# alb32r003x register map
Vendor: ALB; Series: ALB RT SoC
CPU: ALB XF, little endian
Registers are 32-bit, access not given, reset 0x0 unless marked. A register's access mark holds for its fields unless they carry their own. Offsets are from the block's base; [hi:lo] are bit positions.

## EQEP1
Base 0x21010000
Same registers: EQEP2 0x21010400
0x00 QPOSCNT
  [31:0] QPOSCNT — Position Counter
0x04 QPOSINIT
  [31:0] QPOSINIT — Position Counter Init
0x08 QPOSMAX
  [31:0] QPOSMAX — Maximum Position Count
0x0C QPOSCMP
  [31:0] QPOSCMP — Position Compare
0x10 QPOSILAT
  [31:0] QPOSILAT — Index Position Latch
0x14 QPOSSLAT
  [31:0] QPOSSLAT — Strobe Position Latch
0x18 QPOSLAT
  [31:0] QPOSLAT — Position Latch
0x1C QUTMR
  [31:0] QUTMR — QEP Unit Timer
0x20 QUPRD
  [31:0] QUPRD — QEP Unit Period
0x24 QWDTMR 16-bit
  [15:0] QWDTMR — QEP Watchdog Timer
0x26 QWDPRD 16-bit
  [15:0] QWDPRD — QEP Watchdog Period
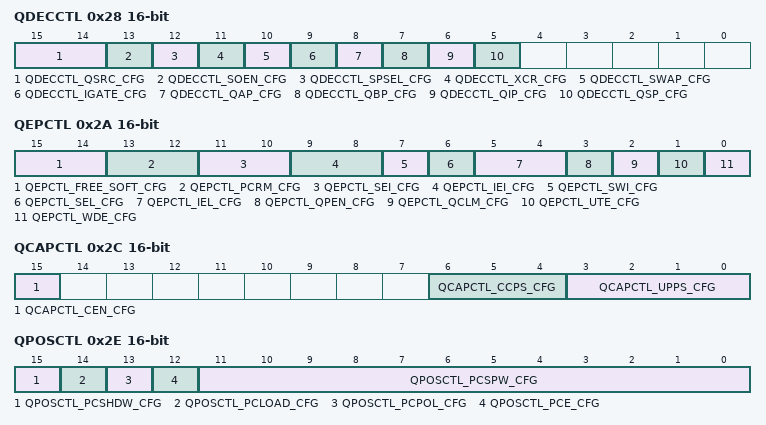
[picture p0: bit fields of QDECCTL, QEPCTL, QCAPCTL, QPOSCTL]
0x28 QDECCTL 16-bit
  [15:14] QDECCTL_QSRC_CFG — Position-counter source selection
  [13] QDECCTL_SOEN_CFG — Sync output-enable
  [12] QDECCTL_SPSEL_CFG — Sync output pin selection
  [11] QDECCTL_XCR_CFG — External Clock Rate
  [10] QDECCTL_SWAP_CFG — CLK/DIR Signal Source for Position Counter
  [9] QDECCTL_IGATE_CFG — Index pulse gating option
  [8] QDECCTL_QAP_CFG — Sync output-enable
  [7] QDECCTL_QBP_CFG — Sync output pin selection
  [6] QDECCTL_QIP_CFG — External Clock Rate
  [5] QDECCTL_QSP_CFG — CLK/DIR Signal Source for Position Counter
0x2A QEPCTL 16-bit
  [15:14] QEPCTL_FREE_SOFT_CFG — Emulation mode
  [13:12] QEPCTL_PCRM_CFG — Postion counter reset
  [11:10] QEPCTL_SEI_CFG — Strobe event initialization of position counter
  [9:8] QEPCTL_IEI_CFG — Index event init of position count
  [7] QEPCTL_SWI_CFG — Software init position counter
  [6] QEPCTL_SEL_CFG — Strobe event latch of position counter
  [5:4] QEPCTL_IEL_CFG — Index event latch of position counter (software index marker)
  [3] QEPCTL_QPEN_CFG — Quadrature position counter enable/software reset
  [2] QEPCTL_QCLM_CFG — QEP capture latch mode
  [1] QEPCTL_UTE_CFG — QEP unit timer enable
  [0] QEPCTL_WDE_CFG — QEP watchdog enable
0x2C QCAPCTL 16-bit
  [15] QCAPCTL_CEN_CFG — Enable eQEP capture
  [6:4] QCAPCTL_CCPS_CFG — eQEP capture timer clock prescaler
  [3:0] QCAPCTL_UPPS_CFG — Unit position event prescaler
0x2E QPOSCTL 16-bit
  [15] QPOSCTL_PCSHDW_CFG — Position compare of shadow enable
  [14] QPOSCTL_PCLOAD_CFG — Position compare of shadow load
  [13] QPOSCTL_PCPOL_CFG — Polarity of sync output
  [12] QPOSCTL_PCE_CFG — Position compare enable/disable
  [11:0] QPOSCTL_PCSPW_CFG — Select-position-compare sync output pulse width
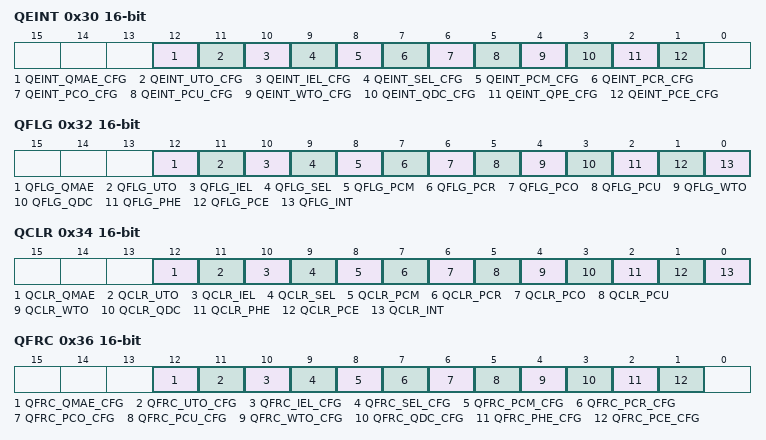
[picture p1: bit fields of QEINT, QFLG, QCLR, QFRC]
0x30 QEINT 16-bit
  [12] QEINT_QMAE_CFG — QMA Error Interrupt enable
  [11] QEINT_UTO_CFG — Unit time out interrupt enable
  [10] QEINT_IEL_CFG — Index event latch interrupt enable
  [9] QEINT_SEL_CFG — Strobe event latch interrupt enable
  [8] QEINT_PCM_CFG — Position-compare match interrupt enable
  [7] QEINT_PCR_CFG — Position-compare ready interrupt enable
  [6] QEINT_PCO_CFG — Position counter overflow interrupt enable
  [5] QEINT_PCU_CFG — Position counter underflow interrupt enable
  [4] QEINT_WTO_CFG — Watchdog time out interrupt enable
  [3] QEINT_QDC_CFG — Quadrature direction change interrupt enable
  [2] QEINT_QPE_CFG — Quadrature phase error interrupt enable
  [1] QEINT_PCE_CFG — Position counter error interrupt enable
0x32 QFLG 16-bit
  [12] QFLG_QMAE — QMA Error interrupt flag
  [11] QFLG_UTO — Unit time out interrupt flag
  [10] QFLG_IEL — Index event latch interrupt flag
  [9] QFLG_SEL — Strobe event latch interrupt flag
  [8] QFLG_PCM — eQEP compare match event interrupt flag
  [7] QFLG_PCR — Position-compare ready interrupt flag
  [6] QFLG_PCO — Position counter overflow interrupt flag
  [5] QFLG_PCU — Position counter underflow interrupt flag
  [4] QFLG_WTO — Watchdog timeout interrupt flag
  [3] QFLG_QDC — Quadrature direction change interrupt flag
  [2] QFLG_PHE — Quadrature phase error interrupt flag
  [1] QFLG_PCE — Position counter error interrupt flag
  [0] QFLG_INT — Global interrupt status flag
0x34 QCLR 16-bit
  [12] QCLR_QMAE — Clear QMA Error interrupt flag
  [11] QCLR_UTO — Clear unit time out interrupt flag
  [10] QCLR_IEL — Clear index event latch interrupt flag
  [9] QCLR_SEL — Clear strobe event latch interrupt flag
  [8] QCLR_PCM — Clear eQEP compare match event interrupt flag
  [7] QCLR_PCR — Clear position-compare ready interrupt flag
  [6] QCLR_PCO — Clear position counter overflow interrupt flag
  [5] QCLR_PCU — Clear position counter underflow interrupt flag
  [4] QCLR_WTO — Clear watchdog timeout interrupt flag
  [3] QCLR_QDC — Clear quadrature direction change interrupt flag
  [2] QCLR_PHE — Clear quadrature phase error interrupt flag
  [1] QCLR_PCE — Clear position counter error interrupt flag
  [0] QCLR_INT — Global interrupt clear flag
0x36 QFRC 16-bit
  [12] QFRC_QMAE_CFG — Force QMA error interrupt
  [11] QFRC_UTO_CFG — Force unit time out interrupt
  [10] QFRC_IEL_CFG — Force index event latch interrupt
  [9] QFRC_SEL_CFG — Force strobe event latch interrupt
  [8] QFRC_PCM_CFG — Force position-compare match interrupt
  [7] QFRC_PCR_CFG — Force position-compare ready interrupt
  [6] QFRC_PCO_CFG — Force position counter overflow interrupt
  [5] QFRC_PCU_CFG — Force position counter underflow interrupt
  [4] QFRC_WTO_CFG — Force watchdog time out interrupt
  [3] QFRC_QDC_CFG — Force quadrature direction change interrupt
  [2] QFRC_PHE_CFG — Force quadrature phase error interrupt
  [1] QFRC_PCE_CFG — Force position counter error interrupt
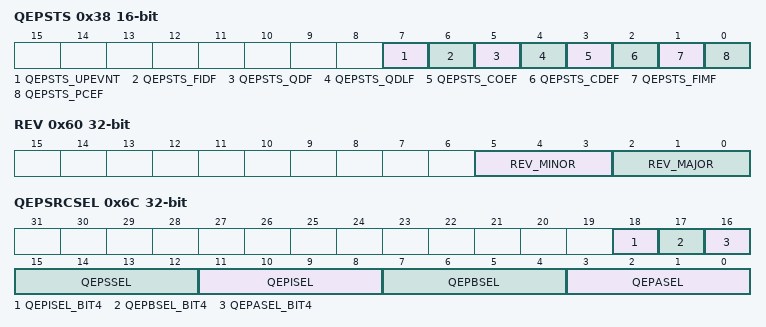
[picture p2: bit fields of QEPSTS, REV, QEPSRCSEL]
0x38 QEPSTS 16-bit
  [7] QEPSTS_UPEVNT — Unit position event flag
  [6] QEPSTS_FIDF — Direction on the first index marker
  [5] QEPSTS_QDF — Quadrature direction flag
  [4] QEPSTS_QDLF — eQEP direction latch flag
  [3] QEPSTS_COEF — Capture overflow error flag
  [2] QEPSTS_CDEF — Capture direction error flag
  [1] QEPSTS_FIMF — First index marker flag
  [0] QEPSTS_PCEF — Position counter error flag.
0x3A QCTMR 16-bit
  [15:0] QCTMR — This register provides time base for edge capture unit.
0x3C QCPRD 16-bit
  [15:0] QCPRD — This register holds the period count value between the last
0x3E QCTMRLAT 16-bit
  [15:0] QCTMRLAT — The eQEP capture timer value can be latched into this register
0x40 QCPRDLAT 16-bit
  [15:0] QCPRDLAT — eQEP capture period value can be latched into this register on two
0x60 REV
  [5:3] REV_MINOR — This field specifies the Minor Revision number for the eQEP IP.
  [2:0] REV_MAJOR — This field specifies the Major Revision number for the eQEP IP.
0x64 QEPSTROBESEL
  [1:0] QEPSTROBESEL_CFG — Strobe source select:
0x68 QMACTRL
  [2:0] QMACTRL_MODE_CFG — Select Mode for QMA mode:
0x6C QEPSRCSEL
  [18] QEPISEL_BIT4 — QEPI source select - bit[4]
  [17] QEPBSEL_BIT4 — QEPB source select - bit[4]
  [16] QEPASEL_BIT4 — QEPA source select - bit[4]
  [15:12] QEPSSEL — QEP Strobe source select:
  [11:8] QEPISEL — QEPI source select:
  [7:4] QEPBSEL — QEPB source select:
  [3:0] QEPASEL — QEPA source select:
